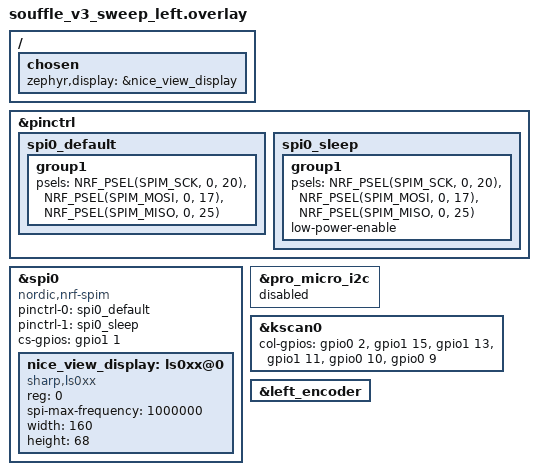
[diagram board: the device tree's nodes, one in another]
/*
 * Copyright (c) 2025 The ZMK Contributors
 * SPDX-License-Identifier: MIT
 */

#include "souffle_v3_sweep.dtsi"
#include <dt-bindings/led/led.h>

&pinctrl {
    spi0_default: spi0_default {
        group1 {
            psels = <NRF_PSEL(SPIM_SCK, 0, 20)>,
                    <NRF_PSEL(SPIM_MOSI, 0, 17)>,
                    <NRF_PSEL(SPIM_MISO, 0, 25)>;
        };
    };

    spi0_sleep: spi0_sleep {
        group1 {
            psels = <NRF_PSEL(SPIM_SCK, 0, 20)>,
                    <NRF_PSEL(SPIM_MOSI, 0, 17)>,
                    <NRF_PSEL(SPIM_MISO, 0, 25)>;
            low-power-enable;
        };
    };
};

nice_view_spi: &spi0 {
    compatible = "nordic,nrf-spim";
    status = "okay";

    pinctrl-0 = <&spi0_default>;
    pinctrl-1 = <&spi0_sleep>;
    pinctrl-names = "default", "sleep";

    cs-gpios = <&gpio1 1 GPIO_ACTIVE_HIGH>; // P1.01 for CS

    nice_view_display: ls0xx@0 {
        compatible = "sharp,ls0xx"; // Sharp LS011B7DH03
        reg = <0>;
        spi-max-frequency = <1000000>;
        width = <160>;
        height = <68>;
    };
};

&pro_micro_i2c {
    status = "disabled";
};

/ {
    chosen {
        zephyr,display = &nice_view_display;
    };
};

&kscan0 {
    col-gpios
        = <&gpio0 2  GPIO_ACTIVE_HIGH> // P0.02 - col0 (corrected - was mirrored)
        , <&gpio1 15 GPIO_ACTIVE_HIGH> // P1.15 - col1
        , <&gpio1 13 GPIO_ACTIVE_HIGH> // P1.13 - col2
        , <&gpio1 11 GPIO_ACTIVE_HIGH> // P1.11 - col3
        , <&gpio0 10 GPIO_ACTIVE_HIGH> // P0.10 - col4
        , <&gpio0 9  GPIO_ACTIVE_HIGH> // P0.09 - col5
        ;
};

&left_encoder {
    status = "okay";
};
